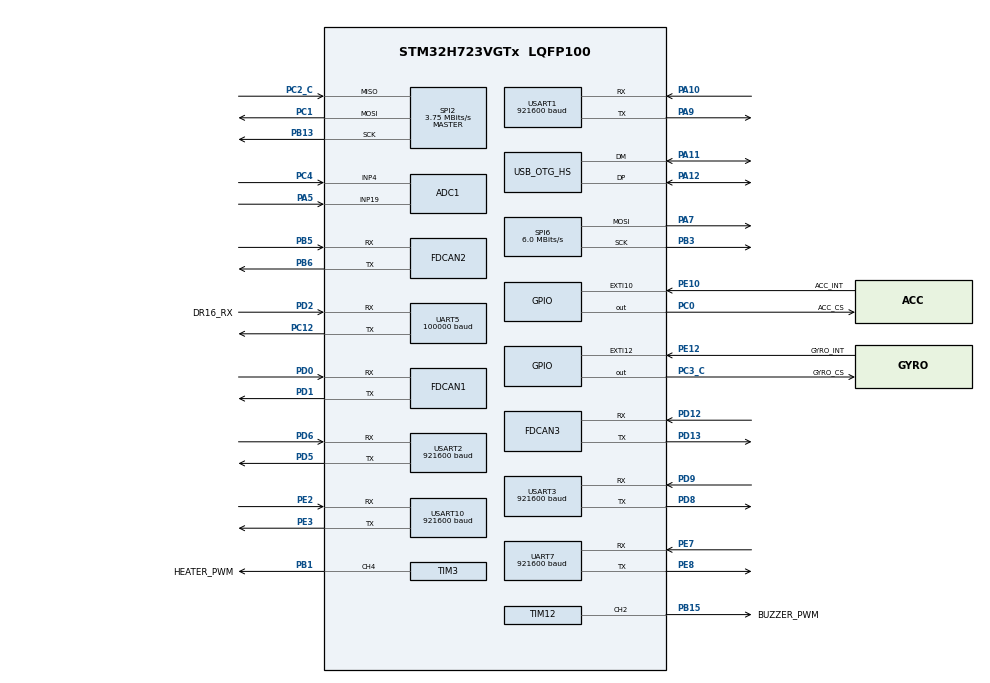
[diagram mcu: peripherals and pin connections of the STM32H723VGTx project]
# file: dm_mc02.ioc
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ADC1.Channel-0\#ChannelRegularConversion=ADC_CHANNEL_4
ADC1.Channel-1\#ChannelRegularConversion=ADC_CHANNEL_19
ADC1.ClockPrescaler=ADC_CLOCK_ASYNC_DIV1
ADC1.ContinuousConvMode=ENABLE
ADC1.ConversionDataManagement=ADC_CONVERSIONDATA_DMA_CIRCULAR
ADC1.NbrOfConversion=2
ADC1.NbrOfConversionFlag=1
ADC1.OffsetNumber-0\#ChannelRegularConversion=ADC_OFFSET_NONE
ADC1.OffsetNumber-1\#ChannelRegularConversion=ADC_OFFSET_NONE
ADC1.OffsetSignedSaturation-0\#ChannelRegularConversion=DISABLE
ADC1.OffsetSignedSaturation-1\#ChannelRegularConversion=DISABLE
ADC1.Rank-0\#ChannelRegularConversion=1
ADC1.Rank-1\#ChannelRegularConversion=2
ADC1.SamplingTime-0\#ChannelRegularConversion=ADC_SAMPLETIME_32CYCLES_5
ADC1.SamplingTime-1\#ChannelRegularConversion=ADC_SAMPLETIME_32CYCLES_5
ADC1.master=1
CORTEX_M7.CPU_DCache=Enabled
CORTEX_M7.CPU_ICache=Enabled
CORTEX_M7.default_mode_Activation=1
Dma.ADC1.0.Direction=DMA_PERIPH_TO_MEMORY
Dma.ADC1.0.EventEnable=DISABLE
Dma.ADC1.0.FIFOMode=DMA_FIFOMODE_DISABLE
Dma.ADC1.0.Instance=DMA1_Stream0
Dma.ADC1.0.MemDataAlignment=DMA_MDATAALIGN_HALFWORD
Dma.ADC1.0.MemInc=DMA_MINC_ENABLE
Dma.ADC1.0.Mode=DMA_CIRCULAR
Dma.ADC1.0.PeriphDataAlignment=DMA_PDATAALIGN_HALFWORD
Dma.ADC1.0.PeriphInc=DMA_PINC_DISABLE
Dma.ADC1.0.Polarity=HAL_DMAMUX_REQ_GEN_RISING
Dma.ADC1.0.Priority=DMA_PRIORITY_LOW
Dma.ADC1.0.RequestNumber=1
Dma.ADC1.0.SignalID=NONE
Dma.ADC1.0.SyncEnable=DISABLE
Dma.ADC1.0.SyncPolarity=HAL_DMAMUX_SYNC_NO_EVENT
Dma.ADC1.0.SyncRequestNumber=1
Dma.ADC1.0.SyncSignalID=NONE
Dma.Request0=ADC1
Dma.Request1=UART5_RX
Dma.Request10=USART10_RX
Dma.Request11=USART10_TX
Dma.Request12=USART1_RX
Dma.Request13=USART1_TX
Dma.Request2=SPI2_RX
Dma.Request3=SPI2_TX
Dma.Request4=UART7_RX
Dma.Request5=UART7_TX
Dma.Request6=USART2_RX
Dma.Request7=USART2_TX
Dma.Request8=USART3_RX
Dma.Request9=USART3_TX
Dma.SPI2_RX.2.Direction=DMA_PERIPH_TO_MEMORY
Dma.SPI2_RX.2.EventEnable=DISABLE
Dma.SPI2_RX.2.FIFOMode=DMA_FIFOMODE_DISABLE
Dma.SPI2_RX.2.Instance=DMA1_Stream2
Dma.SPI2_RX.2.MemDataAlignment=DMA_MDATAALIGN_BYTE
Dma.SPI2_RX.2.MemInc=DMA_MINC_ENABLE
Dma.SPI2_RX.2.Mode=DMA_NORMAL
Dma.SPI2_RX.2.PeriphDataAlignment=DMA_PDATAALIGN_BYTE
Dma.SPI2_RX.2.PeriphInc=DMA_PINC_DISABLE
Dma.SPI2_RX.2.Polarity=HAL_DMAMUX_REQ_GEN_RISING
Dma.SPI2_RX.2.Priority=DMA_PRIORITY_LOW
Dma.SPI2_RX.2.RequestNumber=1
Dma.SPI2_RX.2.SignalID=NONE
Dma.SPI2_RX.2.SyncEnable=DISABLE
Dma.SPI2_RX.2.SyncPolarity=HAL_DMAMUX_SYNC_NO_EVENT
Dma.SPI2_RX.2.SyncRequestNumber=1
Dma.SPI2_RX.2.SyncSignalID=NONE
Dma.SPI2_TX.3.Direction=DMA_MEMORY_TO_PERIPH
Dma.SPI2_TX.3.EventEnable=DISABLE
Dma.SPI2_TX.3.FIFOMode=DMA_FIFOMODE_DISABLE
Dma.SPI2_TX.3.Instance=DMA1_Stream3
Dma.SPI2_TX.3.MemDataAlignment=DMA_MDATAALIGN_BYTE
Dma.SPI2_TX.3.MemInc=DMA_MINC_ENABLE
Dma.SPI2_TX.3.Mode=DMA_NORMAL
Dma.SPI2_TX.3.PeriphDataAlignment=DMA_PDATAALIGN_BYTE
Dma.SPI2_TX.3.PeriphInc=DMA_PINC_DISABLE
Dma.SPI2_TX.3.Polarity=HAL_DMAMUX_REQ_GEN_RISING
Dma.SPI2_TX.3.Priority=DMA_PRIORITY_LOW
Dma.SPI2_TX.3.RequestNumber=1
Dma.SPI2_TX.3.SignalID=NONE
Dma.SPI2_TX.3.SyncEnable=DISABLE
Dma.SPI2_TX.3.SyncPolarity=HAL_DMAMUX_SYNC_NO_EVENT
Dma.SPI2_TX.3.SyncRequestNumber=1
Dma.SPI2_TX.3.SyncSignalID=NONE
Dma.UART5_RX.1.Direction=DMA_PERIPH_TO_MEMORY
Dma.UART5_RX.1.EventEnable=DISABLE
Dma.UART5_RX.1.FIFOMode=DMA_FIFOMODE_DISABLE
Dma.UART5_RX.1.Instance=DMA1_Stream1
Dma.UART5_RX.1.MemDataAlignment=DMA_MDATAALIGN_BYTE
Dma.UART5_RX.1.MemInc=DMA_MINC_ENABLE
Dma.UART5_RX.1.Mode=DMA_NORMAL
Dma.UART5_RX.1.PeriphDataAlignment=DMA_PDATAALIGN_BYTE
Dma.UART5_RX.1.PeriphInc=DMA_PINC_DISABLE
Dma.UART5_RX.1.Polarity=HAL_DMAMUX_REQ_GEN_RISING
Dma.UART5_RX.1.Priority=DMA_PRIORITY_LOW
Dma.UART5_RX.1.RequestNumber=1
Dma.UART5_RX.1.SignalID=NONE
Dma.UART5_RX.1.SyncEnable=DISABLE
Dma.UART5_RX.1.SyncPolarity=HAL_DMAMUX_SYNC_NO_EVENT
Dma.UART5_RX.1.SyncRequestNumber=1
Dma.UART5_RX.1.SyncSignalID=NONE
Dma.UART7_RX.4.Direction=DMA_PERIPH_TO_MEMORY
Dma.UART7_RX.4.EventEnable=DISABLE
Dma.UART7_RX.4.FIFOMode=DMA_FIFOMODE_DISABLE
Dma.UART7_RX.4.Instance=DMA1_Stream4
Dma.UART7_RX.4.MemDataAlignment=DMA_MDATAALIGN_BYTE
Dma.UART7_RX.4.MemInc=DMA_MINC_ENABLE
Dma.UART7_RX.4.Mode=DMA_NORMAL
Dma.UART7_RX.4.PeriphDataAlignment=DMA_PDATAALIGN_BYTE
Dma.UART7_RX.4.PeriphInc=DMA_PINC_DISABLE
Dma.UART7_RX.4.Polarity=HAL_DMAMUX_REQ_GEN_RISING
Dma.UART7_RX.4.Priority=DMA_PRIORITY_LOW
Dma.UART7_RX.4.RequestNumber=1
Dma.UART7_RX.4.SignalID=NONE
Dma.UART7_RX.4.SyncEnable=DISABLE
Dma.UART7_RX.4.SyncPolarity=HAL_DMAMUX_SYNC_NO_EVENT
Dma.UART7_RX.4.SyncRequestNumber=1
Dma.UART7_RX.4.SyncSignalID=NONE
Dma.UART7_TX.5.Direction=DMA_MEMORY_TO_PERIPH
Dma.UART7_TX.5.EventEnable=DISABLE
Dma.UART7_TX.5.FIFOMode=DMA_FIFOMODE_DISABLE
Dma.UART7_TX.5.Instance=DMA1_Stream5
Dma.UART7_TX.5.MemDataAlignment=DMA_MDATAALIGN_BYTE
Dma.UART7_TX.5.MemInc=DMA_MINC_ENABLE
Dma.UART7_TX.5.Mode=DMA_NORMAL
Dma.UART7_TX.5.PeriphDataAlignment=DMA_PDATAALIGN_BYTE
Dma.UART7_TX.5.PeriphInc=DMA_PINC_DISABLE
Dma.UART7_TX.5.Polarity=HAL_DMAMUX_REQ_GEN_RISING
Dma.UART7_TX.5.Priority=DMA_PRIORITY_LOW
Dma.UART7_TX.5.RequestNumber=1
Dma.UART7_TX.5.SignalID=NONE
Dma.UART7_TX.5.SyncEnable=DISABLE
Dma.UART7_TX.5.SyncPolarity=HAL_DMAMUX_SYNC_NO_EVENT
Dma.UART7_TX.5.SyncRequestNumber=1
Dma.UART7_TX.5.SyncSignalID=NONE
Dma.USART10_RX.10.Direction=DMA_PERIPH_TO_MEMORY
Dma.USART10_RX.10.EventEnable=DISABLE
Dma.USART10_RX.10.FIFOMode=DMA_FIFOMODE_DISABLE
Dma.USART10_RX.10.Instance=DMA2_Stream4
Dma.USART10_RX.10.MemDataAlignment=DMA_MDATAALIGN_BYTE
Dma.USART10_RX.10.MemInc=DMA_MINC_ENABLE
Dma.USART10_RX.10.Mode=DMA_NORMAL
Dma.USART10_RX.10.PeriphDataAlignment=DMA_PDATAALIGN_BYTE
Dma.USART10_RX.10.PeriphInc=DMA_PINC_DISABLE
Dma.USART10_RX.10.Polarity=HAL_DMAMUX_REQ_GEN_RISING
Dma.USART10_RX.10.Priority=DMA_PRIORITY_LOW
Dma.USART10_RX.10.RequestNumber=1
Dma.USART10_RX.10.SignalID=NONE
Dma.USART10_RX.10.SyncEnable=DISABLE
Dma.USART10_RX.10.SyncPolarity=HAL_DMAMUX_SYNC_NO_EVENT
Dma.USART10_RX.10.SyncRequestNumber=1
Dma.USART10_RX.10.SyncSignalID=NONE
Dma.USART10_TX.11.Direction=DMA_MEMORY_TO_PERIPH
Dma.USART10_TX.11.EventEnable=DISABLE
Dma.USART10_TX.11.FIFOMode=DMA_FIFOMODE_DISABLE
Dma.USART10_TX.11.Instance=DMA2_Stream5
Dma.USART10_TX.11.MemDataAlignment=DMA_MDATAALIGN_BYTE
Dma.USART10_TX.11.MemInc=DMA_MINC_ENABLE
Dma.USART10_TX.11.Mode=DMA_NORMAL
Dma.USART10_TX.11.PeriphDataAlignment=DMA_PDATAALIGN_BYTE
Dma.USART10_TX.11.PeriphInc=DMA_PINC_DISABLE
Dma.USART10_TX.11.Polarity=HAL_DMAMUX_REQ_GEN_RISING
Dma.USART10_TX.11.Priority=DMA_PRIORITY_LOW
Dma.USART10_TX.11.RequestNumber=1
Dma.USART10_TX.11.SignalID=NONE
Dma.USART10_TX.11.SyncEnable=DISABLE
Dma.USART10_TX.11.SyncPolarity=HAL_DMAMUX_SYNC_NO_EVENT
Dma.USART10_TX.11.SyncRequestNumber=1
Dma.USART10_TX.11.SyncSignalID=NONE
Dma.USART1_RX.12.Direction=DMA_PERIPH_TO_MEMORY
Dma.USART1_RX.12.EventEnable=DISABLE
Dma.USART1_RX.12.FIFOMode=DMA_FIFOMODE_DISABLE
Dma.USART1_RX.12.Instance=DMA1_Stream6
Dma.USART1_RX.12.MemDataAlignment=DMA_MDATAALIGN_BYTE
Dma.USART1_RX.12.MemInc=DMA_MINC_ENABLE
Dma.USART1_RX.12.Mode=DMA_NORMAL
Dma.USART1_RX.12.PeriphDataAlignment=DMA_PDATAALIGN_BYTE
Dma.USART1_RX.12.PeriphInc=DMA_PINC_DISABLE
Dma.USART1_RX.12.Polarity=HAL_DMAMUX_REQ_GEN_RISING
Dma.USART1_RX.12.Priority=DMA_PRIORITY_LOW
Dma.USART1_RX.12.RequestNumber=1
Dma.USART1_RX.12.SignalID=NONE
Dma.USART1_RX.12.SyncEnable=DISABLE
Dma.USART1_RX.12.SyncPolarity=HAL_DMAMUX_SYNC_NO_EVENT
Dma.USART1_RX.12.SyncRequestNumber=1
Dma.USART1_RX.12.SyncSignalID=NONE
Dma.USART1_TX.13.Direction=DMA_MEMORY_TO_PERIPH
Dma.USART1_TX.13.EventEnable=DISABLE
Dma.USART1_TX.13.FIFOMode=DMA_FIFOMODE_DISABLE
Dma.USART1_TX.13.Instance=DMA1_Stream7
Dma.USART1_TX.13.MemDataAlignment=DMA_MDATAALIGN_BYTE
Dma.USART1_TX.13.MemInc=DMA_MINC_ENABLE
Dma.USART1_TX.13.Mode=DMA_NORMAL
Dma.USART1_TX.13.PeriphDataAlignment=DMA_PDATAALIGN_BYTE
Dma.USART1_TX.13.PeriphInc=DMA_PINC_DISABLE
Dma.USART1_TX.13.Polarity=HAL_DMAMUX_REQ_GEN_RISING
Dma.USART1_TX.13.Priority=DMA_PRIORITY_LOW
Dma.USART1_TX.13.RequestNumber=1
Dma.USART1_TX.13.SignalID=NONE
Dma.USART1_TX.13.SyncEnable=DISABLE
Dma.USART1_TX.13.SyncPolarity=HAL_DMAMUX_SYNC_NO_EVENT
Dma.USART1_TX.13.SyncRequestNumber=1
Dma.USART1_TX.13.SyncSignalID=NONE
Dma.USART2_RX.6.Direction=DMA_PERIPH_TO_MEMORY
Dma.USART2_RX.6.EventEnable=DISABLE
Dma.USART2_RX.6.FIFOMode=DMA_FIFOMODE_DISABLE
Dma.USART2_RX.6.Instance=DMA2_Stream0
Dma.USART2_RX.6.MemDataAlignment=DMA_MDATAALIGN_BYTE
Dma.USART2_RX.6.MemInc=DMA_MINC_ENABLE
Dma.USART2_RX.6.Mode=DMA_NORMAL
Dma.USART2_RX.6.PeriphDataAlignment=DMA_PDATAALIGN_BYTE
Dma.USART2_RX.6.PeriphInc=DMA_PINC_DISABLE
Dma.USART2_RX.6.Polarity=HAL_DMAMUX_REQ_GEN_RISING
Dma.USART2_RX.6.Priority=DMA_PRIORITY_LOW
Dma.USART2_RX.6.RequestNumber=1
Dma.USART2_RX.6.SignalID=NONE
Dma.USART2_RX.6.SyncEnable=DISABLE
Dma.USART2_RX.6.SyncPolarity=HAL_DMAMUX_SYNC_NO_EVENT
Dma.USART2_RX.6.SyncRequestNumber=1
Dma.USART2_RX.6.SyncSignalID=NONE
Dma.USART2_TX.7.Direction=DMA_MEMORY_TO_PERIPH
Dma.USART2_TX.7.EventEnable=DISABLE
Dma.USART2_TX.7.FIFOMode=DMA_FIFOMODE_DISABLE
Dma.USART2_TX.7.Instance=DMA2_Stream1
Dma.USART2_TX.7.MemDataAlignment=DMA_MDATAALIGN_BYTE
Dma.USART2_TX.7.MemInc=DMA_MINC_ENABLE
Dma.USART2_TX.7.Mode=DMA_NORMAL
Dma.USART2_TX.7.PeriphDataAlignment=DMA_PDATAALIGN_BYTE
Dma.USART2_TX.7.PeriphInc=DMA_PINC_DISABLE
Dma.USART2_TX.7.Polarity=HAL_DMAMUX_REQ_GEN_RISING
Dma.USART2_TX.7.Priority=DMA_PRIORITY_LOW
Dma.USART2_TX.7.RequestNumber=1
Dma.USART2_TX.7.SignalID=NONE
Dma.USART2_TX.7.SyncEnable=DISABLE
Dma.USART2_TX.7.SyncPolarity=HAL_DMAMUX_SYNC_NO_EVENT
Dma.USART2_TX.7.SyncRequestNumber=1
Dma.USART2_TX.7.SyncSignalID=NONE
Dma.USART3_RX.8.Direction=DMA_PERIPH_TO_MEMORY
Dma.USART3_RX.8.EventEnable=DISABLE
Dma.USART3_RX.8.FIFOMode=DMA_FIFOMODE_DISABLE
Dma.USART3_RX.8.Instance=DMA2_Stream2
Dma.USART3_RX.8.MemDataAlignment=DMA_MDATAALIGN_BYTE
Dma.USART3_RX.8.MemInc=DMA_MINC_ENABLE
Dma.USART3_RX.8.Mode=DMA_NORMAL
Dma.USART3_RX.8.PeriphDataAlignment=DMA_PDATAALIGN_BYTE
Dma.USART3_RX.8.PeriphInc=DMA_PINC_DISABLE
Dma.USART3_RX.8.Polarity=HAL_DMAMUX_REQ_GEN_RISING
Dma.USART3_RX.8.Priority=DMA_PRIORITY_LOW
Dma.USART3_RX.8.RequestNumber=1
Dma.USART3_RX.8.SignalID=NONE
Dma.USART3_RX.8.SyncEnable=DISABLE
Dma.USART3_RX.8.SyncPolarity=HAL_DMAMUX_SYNC_NO_EVENT
Dma.USART3_RX.8.SyncRequestNumber=1
Dma.USART3_RX.8.SyncSignalID=NONE
Dma.USART3_TX.9.Direction=DMA_MEMORY_TO_PERIPH
Dma.USART3_TX.9.EventEnable=DISABLE
Dma.USART3_TX.9.FIFOMode=DMA_FIFOMODE_DISABLE
Dma.USART3_TX.9.Instance=DMA2_Stream3
Dma.USART3_TX.9.MemDataAlignment=DMA_MDATAALIGN_BYTE
Dma.USART3_TX.9.MemInc=DMA_MINC_ENABLE
Dma.USART3_TX.9.Mode=DMA_NORMAL
Dma.USART3_TX.9.PeriphDataAlignment=DMA_PDATAALIGN_BYTE
Dma.USART3_TX.9.PeriphInc=DMA_PINC_DISABLE
Dma.USART3_TX.9.Polarity=HAL_DMAMUX_REQ_GEN_RISING
Dma.USART3_TX.9.Priority=DMA_PRIORITY_LOW
Dma.USART3_TX.9.RequestNumber=1
Dma.USART3_TX.9.SignalID=NONE
Dma.USART3_TX.9.SyncEnable=DISABLE
Dma.USART3_TX.9.SyncPolarity=HAL_DMAMUX_SYNC_NO_EVENT
Dma.USART3_TX.9.SyncRequestNumber=1
Dma.USART3_TX.9.SyncSignalID=NONE
FDCAN1.AutoRetransmission=ENABLE
FDCAN1.CalculateBaudRateNominal=1000000
FDCAN1.CalculateTimeBitNominal=1000
FDCAN1.CalculateTimeQuantumNominal=25.0
FDCAN1.NominalPrescaler=3
FDCAN1.NominalTimeSeg1=29
FDCAN1.NominalTimeSeg2=10
FDCAN1.RxFifo0ElmtsNbr=32
FDCAN1.StdFiltersNbr=1
FDCAN1.TxFifoQueueElmtsNbr=32
FDCAN2.AutoRetransmission=ENABLE
FDCAN2.CalculateBaudRateNominal=1000000
FDCAN2.CalculateTimeBitNominal=1000
FDCAN2.CalculateTimeQuantumNominal=25.0
FDCAN2.MessageRAMOffset=0x406
FDCAN2.NominalPrescaler=3
FDCAN2.NominalTimeSeg1=29
FDCAN2.NominalTimeSeg2=10
FDCAN2.ProtocolException=DISABLE
FDCAN2.RxFifo1ElmtsNbr=32
FDCAN2.StdFiltersNbr=1
FDCAN2.TransmitPause=DISABLE
FDCAN2.TxEventsNbr=8
FDCAN2.TxFifoQueueElmtsNbr=32
FDCAN3.AutoRetransmission=ENABLE
FDCAN3.CalculateBaudRateNominal=1000000
FDCAN3.CalculateTimeBitNominal=1000
FDCAN3.CalculateTimeQuantumNominal=25.0
FDCAN3.MessageRAMOffset=0x812
FDCAN3.NominalPrescaler=3
FDCAN3.NominalTimeSeg1=29
FDCAN3.NominalTimeSeg2=10
FDCAN3.RxFifo1ElmtsNbr=32
FDCAN3.StdFiltersNbr=1
FDCAN3.TxEventsNbr=4
FDCAN3.TxFifoQueueElmtsNbr=32
FREERTOS.Tasks01=defaultTask,24,128,StartDefaultTask,Default,NULL,Dynamic,NULL,NULL
Mcu.Family=STM32H7
Mcu.Name=STM32H723VGTx
Mcu.Package=LQFP100
NVIC.DMA1_Stream0_IRQn=true\:5\:0\:false\:false\:true\:true\:false\:true\:true
NVIC.DMA1_Stream1_IRQn=true\:5\:0\:false\:false\:true\:true\:false\:true\:true
NVIC.DMA1_Stream2_IRQn=true\:5\:0\:false\:false\:true\:true\:false\:true\:true
NVIC.DMA1_Stream3_IRQn=true\:5\:0\:false\:false\:true\:true\:false\:true\:true
NVIC.DMA1_Stream4_IRQn=true\:5\:0\:false\:false\:true\:true\:false\:true\:true
NVIC.DMA1_Stream5_IRQn=true\:5\:0\:false\:false\:true\:true\:false\:true\:true
NVIC.DMA1_Stream6_IRQn=true\:5\:0\:false\:false\:true\:true\:false\:true\:true
NVIC.DMA1_Stream7_IRQn=true\:5\:0\:false\:false\:true\:true\:false\:true\:true
NVIC.DMA2_Stream0_IRQn=true\:5\:0\:false\:false\:true\:true\:false\:true\:true
NVIC.DMA2_Stream1_IRQn=true\:5\:0\:false\:false\:true\:true\:false\:true\:true
NVIC.DMA2_Stream2_IRQn=true\:5\:0\:false\:false\:true\:true\:false\:true\:true
NVIC.DMA2_Stream3_IRQn=true\:5\:0\:false\:false\:true\:true\:false\:true\:true
NVIC.DMA2_Stream4_IRQn=true\:5\:0\:false\:false\:true\:true\:false\:true\:true
NVIC.DMA2_Stream5_IRQn=true\:5\:0\:false\:false\:true\:true\:false\:true\:true
NVIC.EXTI15_10_IRQn=true\:5\:0\:true\:false\:true\:true\:true\:true\:true
NVIC.FDCAN1_IT0_IRQn=true\:5\:0\:false\:false\:true\:true\:true\:true\:true
NVIC.FDCAN1_IT1_IRQn=true\:5\:0\:false\:false\:true\:true\:true\:true\:true
NVIC.FDCAN2_IT0_IRQn=true\:5\:0\:false\:false\:true\:true\:true\:true\:true
NVIC.FDCAN2_IT1_IRQn=true\:5\:0\:false\:false\:true\:true\:true\:true\:true
NVIC.FDCAN3_IT0_IRQn=true\:5\:0\:false\:false\:true\:true\:true\:true\:true
NVIC.FDCAN3_IT1_IRQn=true\:5\:0\:false\:false\:true\:true\:true\:true\:true
NVIC.OTG_HS_IRQn=true\:5\:0\:false\:false\:true\:true\:false\:true\:true
NVIC.PriorityGroup=NVIC_PRIORITYGROUP_4
NVIC.SPI2_IRQn=true\:5\:0\:false\:false\:true\:true\:false\:true\:true
NVIC.TIM4_IRQn=true\:15\:0\:false\:false\:true\:false\:false\:true\:true
NVIC.TimeBase=TIM4_IRQn
NVIC.TimeBaseIP=TIM4
NVIC.UART5_IRQn=true\:5\:0\:false\:false\:true\:true\:true\:true\:true
NVIC.UART7_IRQn=true\:5\:0\:false\:false\:true\:true\:true\:true\:true
NVIC.USART10_IRQn=true\:5\:0\:false\:false\:true\:true\:true\:true\:true
NVIC.USART2_IRQn=true\:5\:0\:false\:false\:true\:true\:true\:true\:true
NVIC.USART3_IRQn=true\:5\:0\:false\:false\:true\:true\:true\:true\:true
PA10.GPIO_PuPd=GPIO_PULLUP
PA10.Mode=Asynchronous
PA10.Signal=USART1_RX
PA11.Mode=Device_Only_FS
PA11.Signal=USB_OTG_HS_DM
PA12.Mode=Device_Only_FS
PA12.Signal=USB_OTG_HS_DP
PA5.Signal=ADCx_INP19
PA7.Mode=TX_Only_Simplex_Unidirect_Master
PA7.Signal=SPI6_MOSI
PA9.Mode=Asynchronous
PA9.Signal=USART1_TX
PB1.GPIO_Label=HEATER_PWM
PB1.Signal=S_TIM3_CH4
PB13.GPIO_Speed=GPIO_SPEED_FREQ_VERY_HIGH
PB13.Mode=Full_Duplex_Master
PB13.Signal=SPI2_SCK
PB15.GPIO_Label=BUZZER_PWM
PB15.Signal=S_TIM12_CH2
PB3(JTDO/TRACESWO).Mode=TX_Only_Simplex_Unidirect_Master
PB3(JTDO/TRACESWO).Signal=SPI6_SCK
PB5.Mode=FDCAN_Activate
PB5.Signal=FDCAN2_RX
PB6.Mode=FDCAN_Activate
PB6.Signal=FDCAN2_TX
PC0.GPIO_Label=ACC_CS
PC0.GPIO_Speed=GPIO_SPEED_FREQ_VERY_HIGH
PC0.PinState=GPIO_PIN_SET
PC0.Signal=GPIO_Output
PC1.GPIO_Speed=GPIO_SPEED_FREQ_VERY_HIGH
PC1.Mode=Full_Duplex_Master
PC1.Signal=SPI2_MOSI
PC12.Mode=Asynchronous
PC12.Signal=UART5_TX
PC2_C.GPIO_Speed=GPIO_SPEED_FREQ_VERY_HIGH
PC2_C.Mode=Full_Duplex_Master
PC2_C.Signal=SPI2_MISO
PC3_C.GPIO_Label=GYRO_CS
PC3_C.GPIO_Speed=GPIO_SPEED_FREQ_VERY_HIGH
PC3_C.PinState=GPIO_PIN_SET
PC3_C.Signal=GPIO_Output
PC4.Signal=ADCx_INP4
PD0.Mode=FDCAN_Activate
PD0.Signal=FDCAN1_RX
PD1.Mode=FDCAN_Activate
PD1.Signal=FDCAN1_TX
PD12.Mode=FDCAN_Activate
PD12.Signal=FDCAN3_RX
PD13.Mode=FDCAN_Activate
PD13.Signal=FDCAN3_TX
PD2.GPIO_Label=DR16_RX
PD2.GPIO_PuPd=GPIO_PULLUP
PD2.Mode=Asynchronous
PD2.Signal=UART5_RX
PD5.Mode=Asynchronous
PD5.Signal=USART2_TX
PD6.GPIO_PuPd=GPIO_PULLUP
PD6.Mode=Asynchronous
PD6.Signal=USART2_RX
PD8.Mode=Asynchronous
PD8.Signal=USART3_TX
PD9.GPIO_PuPd=GPIO_PULLUP
PD9.Mode=Asynchronous
PD9.Signal=USART3_RX
PE10.GPIO_Label=ACC_INT
PE10.GPIO_PuPd=GPIO_NOPULL
PE10.Signal=GPXTI10
PE12.GPIO_Label=GYRO_INT
PE12.GPIO_PuPd=GPIO_NOPULL
PE12.Signal=GPXTI12
PE2.GPIO_PuPd=GPIO_PULLUP
PE2.Mode=Asynchronous
PE2.Signal=USART10_RX
PE3.Mode=Asynchronous
PE3.Signal=USART10_TX
PE7.GPIO_PuPd=GPIO_PULLUP
PE7.Mode=Asynchronous
PE7.Signal=UART7_RX
PE8.Mode=Asynchronous
PE8.Signal=UART7_TX
PH0-OSC_IN.Mode=HSE-External-Oscillator
PH0-OSC_IN.Signal=RCC_OSC_IN
PH1-OSC_OUT.Mode=HSE-External-Oscillator
PH1-OSC_OUT.Signal=RCC_OSC_OUT
ProjectManager.HeapSize=0x200
ProjectManager.StackSize=0x400
ProjectManager.TargetToolchain=CMake
RCC.ADCCLockSelection=RCC_ADCCLKSOURCE_PLL3
RCC.ADCFreq_Value=48000000
RCC.APB1Freq_Value=120000000
RCC.APB2Freq_Value=120000000
RCC.APB3Freq_Value=120000000
RCC.APB4Freq_Value=120000000
RCC.CKPERSourceSelection=RCC_CLKPSOURCE_HSE
RCC.CortexFreq_Value=480000000
RCC.D1PPRE=RCC_APB3_DIV2
RCC.D2PPRE1=RCC_APB1_DIV2
RCC.D2PPRE2=RCC_APB2_DIV2
RCC.D3PPRE=RCC_APB4_DIV2
RCC.DIVM1=2
RCC.DIVM2=2
RCC.DIVM3=2
RCC.DIVN1=40
RCC.DIVN2=32
RCC.DIVN3=16
RCC.DIVP1=1
RCC.DIVQ1=4
RCC.DIVR3=4
RCC.HCLKFreq_Value=240000000
RCC.HPRE=RCC_HCLK_DIV2
RCC.HSE_VALUE=24000000
RCC.PLL1_VCI_Range-AdvancedSettings=RCC_PLL1VCIRANGE_3
RCC.PLL1_VCO_SEL-AdvancedSettings=RCC_PLL1VCOWIDE
RCC.PLL2FRACN=0
RCC.PLL2_VCI_Range-AdvancedSettings=RCC_PLL2VCIRANGE_3
RCC.PLL2_VCO_SEL-AdvancedSettings=RCC_PLL2VCOWIDE
RCC.PLL3FRACN=0
RCC.PLL3_VCO_SEL-AdvancedSettings=RCC_PLL3VCOWIDE
RCC.PLLFRACN=0
RCC.PLLSourceVirtual=RCC_PLLSOURCE_HSE
RCC.SPI6CLockSelection=RCC_SPI6CLKSOURCE_HSE
RCC.SYSCLKFreq_VALUE=480000000
RCC.SYSCLKSource=RCC_SYSCLKSOURCE_PLLCLK
RCC.USBCLockSelection=RCC_USBCLKSOURCE_HSI48
RCC.USBFreq_Value=48000000
SH.ADCx_INP19.0=ADC1_INP19,IN19-Single-Ended
SH.ADCx_INP4.0=ADC1_INP4,IN4-Single-Ended
SH.S_TIM12_CH2.0=TIM12_CH2,PWM Generation2 CH2
SH.S_TIM3_CH4.0=TIM3_CH4,PWM Generation4 CH4
SPI2.BaudRatePrescaler=SPI_BAUDRATEPRESCALER_32
SPI2.CLKPhase=SPI_PHASE_2EDGE
SPI2.CLKPolarity=SPI_POLARITY_HIGH
SPI2.CalculateBaudRate=3.75 MBits/s
SPI2.DataSize=SPI_DATASIZE_8BIT
SPI2.Direction=SPI_DIRECTION_2LINES
SPI2.Mode=SPI_MODE_MASTER
SPI2.VirtualType=VM_MASTER
SPI6.BaudRatePrescaler=SPI_BAUDRATEPRESCALER_4
SPI6.CalculateBaudRate=6.0 MBits/s
SPI6.DataSize=SPI_DATASIZE_8BIT
SPI6.Direction=SPI_DIRECTION_2LINES_TXONLY
SPI6.Mode=SPI_MODE_MASTER
SPI6.VirtualType=VM_MASTER
TIM12.Channel-PWM\ Generation2\ CH2=TIM_CHANNEL_2
TIM12.OC2Preload_PWM=DISABLE
TIM12.Period=250-1
TIM12.Prescaler=240-1
TIM3.Channel-PWM\ Generation4\ CH4=TIM_CHANNEL_4
TIM3.Period=10000-1
TIM3.Prescaler=240-1
UART5.BaudRate=100000
UART5.Mode=MODE_RX
UART5.Parity=PARITY_EVEN
UART5.StopBits=UART_STOPBITS_2
UART5.WordLength=WORDLENGTH_9B
UART7.BaudRate=921600
USART1.BaudRate=921600
USART1.VirtualMode-Asynchronous=VM_ASYNC
USART10.BaudRate=921600
USART10.VirtualMode=VM_ASYNC
USART2.BaudRate=921600
USART2.VirtualMode-Asynchronous=VM_ASYNC
USART3.BaudRate=921600
USART3.VirtualMode-Asynchronous=VM_ASYNC
USB_DEVICE.CLASS_NAME_HS=CDC
USB_DEVICE.VirtualMode=Cdc
USB_DEVICE.VirtualModeHS=Cdc_HS
USB_OTG_HS.VirtualMode-Device_Only_FS=Device_Only_FS
VP_FREERTOS_VS_CMSIS_V2.Mode=CMSIS_V2
VP_MEMORYMAP_VS_MEMORYMAP.Mode=CurAppReg
VP_SYS_VS_tim4.Mode=TIM4
VP_USB_DEVICE_VS_USB_DEVICE_CDC_HS.Mode=CDC_HS
board=custom

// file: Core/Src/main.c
/* USER CODE BEGIN Header */
/**
  ******************************************************************************
  * @file           : main.c
  * @brief          : Main program body
  ******************************************************************************
  * @attention
  *
  * Copyright (c) 2026 STMicroelectronics.
  * All rights reserved.
  *
  * This software is licensed under terms that can be found in the LICENSE file
  * in the root directory of this software component.
  * If no LICENSE file comes with this software, it is provided AS-IS.
  *
  ******************************************************************************
  */
/* USER CODE END Header */
#include "main.h"
#include "FreeRTOS.h"
#include "cmsis_os2.h"
#include "usb_device.h"

ADC_HandleTypeDef hadc1;
DMA_HandleTypeDef hdma_adc1;

FDCAN_HandleTypeDef hfdcan1;
FDCAN_HandleTypeDef hfdcan2;
FDCAN_HandleTypeDef hfdcan3;

SPI_HandleTypeDef hspi2;
SPI_HandleTypeDef hspi6;
DMA_HandleTypeDef hdma_spi2_rx;
DMA_HandleTypeDef hdma_spi2_tx;

TIM_HandleTypeDef htim3;
TIM_HandleTypeDef htim12;

UART_HandleTypeDef huart5;
UART_HandleTypeDef huart7;
UART_HandleTypeDef huart1;
UART_HandleTypeDef huart2;
UART_HandleTypeDef huart3;
UART_HandleTypeDef huart10;
DMA_HandleTypeDef hdma_uart5_rx;
DMA_HandleTypeDef hdma_uart7_rx;
DMA_HandleTypeDef hdma_uart7_tx;
DMA_HandleTypeDef hdma_usart1_rx;
DMA_HandleTypeDef hdma_usart1_tx;
DMA_HandleTypeDef hdma_usart2_rx;
DMA_HandleTypeDef hdma_usart2_tx;
DMA_HandleTypeDef hdma_usart3_rx;
DMA_HandleTypeDef hdma_usart3_tx;
DMA_HandleTypeDef hdma_usart10_rx;
DMA_HandleTypeDef hdma_usart10_tx;

/* Definitions for defaultTask */
osThreadId_t defaultTaskHandle;
const osThreadAttr_t defaultTask_attributes = {
  .name = "defaultTask",
  .stack_size = 128 * 4,
  .priority = (osPriority_t) osPriorityNormal,
};

void SystemClock_Config(void);
static void MPU_Config(void);
static void MX_GPIO_Init(void);
static void MX_DMA_Init(void);
static void MX_ADC1_Init(void);
static void MX_UART5_Init(void);
static void MX_FDCAN1_Init(void);
static void MX_FDCAN2_Init(void);
static void MX_FDCAN3_Init(void);
static void MX_SPI2_Init(void);
static void MX_SPI6_Init(void);
static void MX_UART7_Init(void);
static void MX_USART2_UART_Init(void);
static void MX_USART3_UART_Init(void);
static void MX_USART10_UART_Init(void);
static void MX_USART1_UART_Init(void);
static void MX_TIM3_Init(void);
static void MX_TIM12_Init(void);
void StartDefaultTask(void *argument);

int main(void)
{

  /* MPU Configuration--------------------------------------------------------*/
  MPU_Config();

  /* Enable the CPU Cache */

  /* Enable I-Cache---------------------------------------------------------*/
  SCB_EnableICache();

  /* Enable D-Cache---------------------------------------------------------*/
  SCB_EnableDCache();

  /* MCU Configuration--------------------------------------------------------*/

  /* Reset of all peripherals, Initializes the Flash interface and the Systick. */
  HAL_Init();

  /* Configure the system clock */
  SystemClock_Config();

  /* Initialize all configured peripherals */
  MX_GPIO_Init();
  MX_DMA_Init();
  MX_ADC1_Init();
  MX_UART5_Init();
  MX_FDCAN1_Init();
  MX_FDCAN2_Init();
  MX_FDCAN3_Init();
  MX_SPI2_Init();
  MX_SPI6_Init();
  MX_UART7_Init();
  MX_USART2_UART_Init();
  MX_USART3_UART_Init();
  MX_USART10_UART_Init();
  MX_USART1_UART_Init();
  MX_TIM3_Init();
  MX_TIM12_Init();
  /* USER CODE BEGIN 2 */
  __HAL_TIM_SET_COMPARE(&htim3, TIM_CHANNEL_4, 0);
  __HAL_TIM_SET_COMPARE(&htim12, TIM_CHANNEL_2, 0);
  if (HAL_TIM_PWM_Start(&htim3, TIM_CHANNEL_4) != HAL_OK ||
      HAL_TIM_PWM_Start(&htim12, TIM_CHANNEL_2) != HAL_OK)
  {
    Error_Handler();
  }
  if (HAL_FDCAN_ConfigGlobalFilter(&hfdcan1, FDCAN_ACCEPT_IN_RX_FIFO0,
                                   FDCAN_ACCEPT_IN_RX_FIFO0, FDCAN_FILTER_REMOTE,
                                   FDCAN_FILTER_REMOTE) != HAL_OK ||
      HAL_FDCAN_ConfigGlobalFilter(&hfdcan2, FDCAN_ACCEPT_IN_RX_FIFO1,
                                   FDCAN_ACCEPT_IN_RX_FIFO1, FDCAN_FILTER_REMOTE,
                                   FDCAN_FILTER_REMOTE) != HAL_OK ||
      HAL_FDCAN_ConfigGlobalFilter(&hfdcan3, FDCAN_ACCEPT_IN_RX_FIFO1,
                                   FDCAN_ACCEPT_IN_RX_FIFO1, FDCAN_FILTER_REMOTE,
                                   FDCAN_FILTER_REMOTE) != HAL_OK)
  {
    Error_Handler();
  }
  /* USER CODE END 2 */

  /* Init scheduler */
  osKernelInitialize();

  /* Create the thread(s) */
  /* creation of defaultTask */
  defaultTaskHandle = osThreadNew(StartDefaultTask, NULL, &defaultTask_attributes);

  /* Start scheduler */
  osKernelStart();

  /* We should never get here as control is now taken by the scheduler */

  /* Infinite loop */
  while (1)
  {

  }
}

void SystemClock_Config(void)
{
  RCC_OscInitTypeDef RCC_OscInitStruct = {0};
  RCC_ClkInitTypeDef RCC_ClkInitStruct = {0};

  /** Supply configuration update enable
  */
  HAL_PWREx_ConfigSupply(PWR_LDO_SUPPLY);

  /** Configure the main internal regulator output voltage
  */
  __HAL_PWR_VOLTAGESCALING_CONFIG(PWR_REGULATOR_VOLTAGE_SCALE0);

  while(!__HAL_PWR_GET_FLAG(PWR_FLAG_VOSRDY)) {}

  /** Initializes the RCC Oscillators according to the specified parameters
  * in the RCC_OscInitTypeDef structure.
  */
  RCC_OscInitStruct.OscillatorType = RCC_OSCILLATORTYPE_HSI48|RCC_OSCILLATORTYPE_HSE;
  RCC_OscInitStruct.HSEState = RCC_HSE_ON;
  RCC_OscInitStruct.HSI48State = RCC_HSI48_ON;
  RCC_OscInitStruct.PLL.PLLState = RCC_PLL_ON;
  RCC_OscInitStruct.PLL.PLLSource = RCC_PLLSOURCE_HSE;
  RCC_OscInitStruct.PLL.PLLM = 2;
  RCC_OscInitStruct.PLL.PLLN = 40;
  RCC_OscInitStruct.PLL.PLLP = 1;
  RCC_OscInitStruct.PLL.PLLQ = 4;
  RCC_OscInitStruct.PLL.PLLR = 2;
  RCC_OscInitStruct.PLL.PLLRGE = RCC_PLL1VCIRANGE_3;
  RCC_OscInitStruct.PLL.PLLVCOSEL = RCC_PLL1VCOWIDE;
  RCC_OscInitStruct.PLL.PLLFRACN = 0;
  if (HAL_RCC_OscConfig(&RCC_OscInitStruct) != HAL_OK)
  {
    Error_Handler();
  }

  /** Initializes the CPU, AHB and APB buses clocks
  */
  RCC_ClkInitStruct.ClockType = RCC_CLOCKTYPE_HCLK|RCC_CLOCKTYPE_SYSCLK
                              |RCC_CLOCKTYPE_PCLK1|RCC_CLOCKTYPE_PCLK2
                              |RCC_CLOCKTYPE_D3PCLK1|RCC_CLOCKTYPE_D1PCLK1;
  RCC_ClkInitStruct.SYSCLKSource = RCC_SYSCLKSOURCE_PLLCLK;
  RCC_ClkInitStruct.SYSCLKDivider = RCC_SYSCLK_DIV1;
  RCC_ClkInitStruct.AHBCLKDivider = RCC_HCLK_DIV2;
  RCC_ClkInitStruct.APB3CLKDivider = RCC_APB3_DIV2;
  RCC_ClkInitStruct.APB1CLKDivider = RCC_APB1_DIV2;
  RCC_ClkInitStruct.APB2CLKDivider = RCC_APB2_DIV2;
  RCC_ClkInitStruct.APB4CLKDivider = RCC_APB4_DIV2;

  if (HAL_RCC_ClockConfig(&RCC_ClkInitStruct, FLASH_LATENCY_3) != HAL_OK)
  {
    Error_Handler();
  }
}

static void MX_ADC1_Init(void)
{

  ADC_MultiModeTypeDef multimode = {0};
  ADC_ChannelConfTypeDef sConfig = {0};

  /** Common config
  */
  hadc1.Instance = ADC1;
  hadc1.Init.ClockPrescaler = ADC_CLOCK_ASYNC_DIV1;
  hadc1.Init.Resolution = ADC_RESOLUTION_16B;
  hadc1.Init.ScanConvMode = ADC_SCAN_ENABLE;
  hadc1.Init.EOCSelection = ADC_EOC_SINGLE_CONV;
  hadc1.Init.LowPowerAutoWait = DISABLE;
  hadc1.Init.ContinuousConvMode = ENABLE;
  hadc1.Init.NbrOfConversion = 2;
  hadc1.Init.DiscontinuousConvMode = DISABLE;
  hadc1.Init.ExternalTrigConv = ADC_SOFTWARE_START;
  hadc1.Init.ExternalTrigConvEdge = ADC_EXTERNALTRIGCONVEDGE_NONE;
  hadc1.Init.ConversionDataManagement = ADC_CONVERSIONDATA_DMA_CIRCULAR;
  hadc1.Init.Overrun = ADC_OVR_DATA_PRESERVED;
  hadc1.Init.LeftBitShift = ADC_LEFTBITSHIFT_NONE;
  hadc1.Init.OversamplingMode = DISABLE;
  hadc1.Init.Oversampling.Ratio = 1;
  if (HAL_ADC_Init(&hadc1) != HAL_OK)
  {
    Error_Handler();
  }

  /** Configure the ADC multi-mode
  */
  multimode.Mode = ADC_MODE_INDEPENDENT;
  if (HAL_ADCEx_MultiModeConfigChannel(&hadc1, &multimode) != HAL_OK)
  {
    Error_Handler();
  }

  /** Configure Regular Channel
  */
  sConfig.Channel = ADC_CHANNEL_4;
  sConfig.Rank = ADC_REGULAR_RANK_1;
  sConfig.SamplingTime = ADC_SAMPLETIME_32CYCLES_5;
  sConfig.SingleDiff = ADC_SINGLE_ENDED;
  sConfig.OffsetNumber = ADC_OFFSET_NONE;
  sConfig.Offset = 0;
  sConfig.OffsetSignedSaturation = DISABLE;
  if (HAL_ADC_ConfigChannel(&hadc1, &sConfig) != HAL_OK)
  {
    Error_Handler();
  }

  /** Configure Regular Channel
  */
  sConfig.Channel = ADC_CHANNEL_19;
  sConfig.Rank = ADC_REGULAR_RANK_2;
  if (HAL_ADC_ConfigChannel(&hadc1, &sConfig) != HAL_OK)
  {
    Error_Handler();
  }

}

static void MX_FDCAN1_Init(void)
{

  hfdcan1.Instance = FDCAN1;
  hfdcan1.Init.FrameFormat = FDCAN_FRAME_CLASSIC;
  hfdcan1.Init.Mode = FDCAN_MODE_NORMAL;
  hfdcan1.Init.AutoRetransmission = ENABLE;
  hfdcan1.Init.TransmitPause = DISABLE;
  hfdcan1.Init.ProtocolException = DISABLE;
  hfdcan1.Init.NominalPrescaler = 3;
  hfdcan1.Init.NominalSyncJumpWidth = 1;
  hfdcan1.Init.NominalTimeSeg1 = 29;
  hfdcan1.Init.NominalTimeSeg2 = 10;
  hfdcan1.Init.DataPrescaler = 1;
  hfdcan1.Init.DataSyncJumpWidth = 1;
  hfdcan1.Init.DataTimeSeg1 = 1;
  hfdcan1.Init.DataTimeSeg2 = 1;
  hfdcan1.Init.MessageRAMOffset = 0;
  hfdcan1.Init.StdFiltersNbr = 1;
  hfdcan1.Init.ExtFiltersNbr = 0;
  hfdcan1.Init.RxFifo0ElmtsNbr = 32;
  hfdcan1.Init.RxFifo0ElmtSize = FDCAN_DATA_BYTES_8;
  hfdcan1.Init.RxFifo1ElmtsNbr = 0;
  hfdcan1.Init.RxFifo1ElmtSize = FDCAN_DATA_BYTES_8;
  hfdcan1.Init.RxBuffersNbr = 0;
  hfdcan1.Init.RxBufferSize = FDCAN_DATA_BYTES_8;
  hfdcan1.Init.TxEventsNbr = 0;
  hfdcan1.Init.TxBuffersNbr = 0;
  hfdcan1.Init.TxFifoQueueElmtsNbr = 32;
  hfdcan1.Init.TxFifoQueueMode = FDCAN_TX_FIFO_OPERATION;
  hfdcan1.Init.TxElmtSize = FDCAN_DATA_BYTES_8;
  if (HAL_FDCAN_Init(&hfdcan1) != HAL_OK)
  {
    Error_Handler();
  }

}

static void MX_FDCAN2_Init(void)
{

  hfdcan2.Instance = FDCAN2;
  hfdcan2.Init.FrameFormat = FDCAN_FRAME_CLASSIC;
  hfdcan2.Init.Mode = FDCAN_MODE_NORMAL;
  hfdcan2.Init.AutoRetransmission = ENABLE;
  hfdcan2.Init.TransmitPause = DISABLE;
  hfdcan2.Init.ProtocolException = DISABLE;
  hfdcan2.Init.NominalPrescaler = 3;
  hfdcan2.Init.NominalSyncJumpWidth = 1;
  hfdcan2.Init.NominalTimeSeg1 = 29;
  hfdcan2.Init.NominalTimeSeg2 = 10;
  hfdcan2.Init.DataPrescaler = 1;
  hfdcan2.Init.DataSyncJumpWidth = 1;
  hfdcan2.Init.DataTimeSeg1 = 1;
  hfdcan2.Init.DataTimeSeg2 = 1;
  hfdcan2.Init.MessageRAMOffset = 0x406;
  hfdcan2.Init.StdFiltersNbr = 1;
  hfdcan2.Init.ExtFiltersNbr = 0;
  hfdcan2.Init.RxFifo0ElmtsNbr = 0;
  hfdcan2.Init.RxFifo0ElmtSize = FDCAN_DATA_BYTES_8;
  hfdcan2.Init.RxFifo1ElmtsNbr = 32;
  hfdcan2.Init.RxFifo1ElmtSize = FDCAN_DATA_BYTES_8;
  hfdcan2.Init.RxBuffersNbr = 0;
  hfdcan2.Init.RxBufferSize = FDCAN_DATA_BYTES_8;
  hfdcan2.Init.TxEventsNbr = 8;
  hfdcan2.Init.TxBuffersNbr = 0;
  hfdcan2.Init.TxFifoQueueElmtsNbr = 32;
  hfdcan2.Init.TxFifoQueueMode = FDCAN_TX_FIFO_OPERATION;
  hfdcan2.Init.TxElmtSize = FDCAN_DATA_BYTES_8;
  if (HAL_FDCAN_Init(&hfdcan2) != HAL_OK)
  {
    Error_Handler();
  }

}

static void MX_FDCAN3_Init(void)
{

  hfdcan3.Instance = FDCAN3;
  hfdcan3.Init.FrameFormat = FDCAN_FRAME_CLASSIC;
  hfdcan3.Init.Mode = FDCAN_MODE_NORMAL;
  hfdcan3.Init.AutoRetransmission = ENABLE;
  hfdcan3.Init.TransmitPause = DISABLE;
  hfdcan3.Init.ProtocolException = DISABLE;
  hfdcan3.Init.NominalPrescaler = 3;
  hfdcan3.Init.NominalSyncJumpWidth = 1;
  hfdcan3.Init.NominalTimeSeg1 = 29;
  hfdcan3.Init.NominalTimeSeg2 = 10;
  hfdcan3.Init.DataPrescaler = 1;
  hfdcan3.Init.DataSyncJumpWidth = 1;
  hfdcan3.Init.DataTimeSeg1 = 1;
  hfdcan3.Init.DataTimeSeg2 = 1;
  hfdcan3.Init.MessageRAMOffset = 0x812;
  hfdcan3.Init.StdFiltersNbr = 1;
  hfdcan3.Init.ExtFiltersNbr = 0;
  hfdcan3.Init.RxFifo0ElmtsNbr = 0;
  hfdcan3.Init.RxFifo0ElmtSize = FDCAN_DATA_BYTES_8;
  hfdcan3.Init.RxFifo1ElmtsNbr = 32;
  hfdcan3.Init.RxFifo1ElmtSize = FDCAN_DATA_BYTES_8;
  hfdcan3.Init.RxBuffersNbr = 0;
  hfdcan3.Init.RxBufferSize = FDCAN_DATA_BYTES_8;
  hfdcan3.Init.TxEventsNbr = 4;
  hfdcan3.Init.TxBuffersNbr = 0;
  hfdcan3.Init.TxFifoQueueElmtsNbr = 32;
  hfdcan3.Init.TxFifoQueueMode = FDCAN_TX_FIFO_OPERATION;
  hfdcan3.Init.TxElmtSize = FDCAN_DATA_BYTES_8;
  if (HAL_FDCAN_Init(&hfdcan3) != HAL_OK)
  {
    Error_Handler();
  }

}

static void MX_SPI2_Init(void)
{

  /* SPI2 parameter configuration*/
  hspi2.Instance = SPI2;
  hspi2.Init.Mode = SPI_MODE_MASTER;
  hspi2.Init.Direction = SPI_DIRECTION_2LINES;
  hspi2.Init.DataSize = SPI_DATASIZE_8BIT;
  hspi2.Init.CLKPolarity = SPI_POLARITY_HIGH;
  hspi2.Init.CLKPhase = SPI_PHASE_2EDGE;
  hspi2.Init.NSS = SPI_NSS_SOFT;
  hspi2.Init.BaudRatePrescaler = SPI_BAUDRATEPRESCALER_32;
  hspi2.Init.FirstBit = SPI_FIRSTBIT_MSB;
  hspi2.Init.TIMode = SPI_TIMODE_DISABLE;
  hspi2.Init.CRCCalculation = SPI_CRCCALCULATION_DISABLE;
  hspi2.Init.CRCPolynomial = 0x0;
  hspi2.Init.NSSPMode = SPI_NSS_PULSE_ENABLE;
  hspi2.Init.NSSPolarity = SPI_NSS_POLARITY_LOW;
  hspi2.Init.FifoThreshold = SPI_FIFO_THRESHOLD_01DATA;
  hspi2.Init.TxCRCInitializationPattern = SPI_CRC_INITIALIZATION_ALL_ZERO_PATTERN;
  hspi2.Init.RxCRCInitializationPattern = SPI_CRC_INITIALIZATION_ALL_ZERO_PATTERN;
  hspi2.Init.MasterSSIdleness = SPI_MASTER_SS_IDLENESS_00CYCLE;
  hspi2.Init.MasterInterDataIdleness = SPI_MASTER_INTERDATA_IDLENESS_00CYCLE;
  hspi2.Init.MasterReceiverAutoSusp = SPI_MASTER_RX_AUTOSUSP_DISABLE;
  hspi2.Init.MasterKeepIOState = SPI_MASTER_KEEP_IO_STATE_DISABLE;
  hspi2.Init.IOSwap = SPI_IO_SWAP_DISABLE;
  if (HAL_SPI_Init(&hspi2) != HAL_OK)
  {
    Error_Handler();
  }

}

static void MX_SPI6_Init(void)
{

  /* SPI6 parameter configuration*/
  hspi6.Instance = SPI6;
  hspi6.Init.Mode = SPI_MODE_MASTER;
  hspi6.Init.Direction = SPI_DIRECTION_2LINES_TXONLY;
  hspi6.Init.DataSize = SPI_DATASIZE_8BIT;
  hspi6.Init.CLKPolarity = SPI_POLARITY_LOW;
  hspi6.Init.CLKPhase = SPI_PHASE_1EDGE;
  hspi6.Init.NSS = SPI_NSS_SOFT;
  hspi6.Init.BaudRatePrescaler = SPI_BAUDRATEPRESCALER_4;
  hspi6.Init.FirstBit = SPI_FIRSTBIT_MSB;
  hspi6.Init.TIMode = SPI_TIMODE_DISABLE;
  hspi6.Init.CRCCalculation = SPI_CRCCALCULATION_DISABLE;
  hspi6.Init.CRCPolynomial = 0x0;
  hspi6.Init.NSSPMode = SPI_NSS_PULSE_ENABLE;
  hspi6.Init.NSSPolarity = SPI_NSS_POLARITY_LOW;
  hspi6.Init.FifoThreshold = SPI_FIFO_THRESHOLD_01DATA;
  hspi6.Init.TxCRCInitializationPattern = SPI_CRC_INITIALIZATION_ALL_ZERO_PATTERN;
  hspi6.Init.RxCRCInitializationPattern = SPI_CRC_INITIALIZATION_ALL_ZERO_PATTERN;
  hspi6.Init.MasterSSIdleness = SPI_MASTER_SS_IDLENESS_00CYCLE;
  hspi6.Init.MasterInterDataIdleness = SPI_MASTER_INTERDATA_IDLENESS_00CYCLE;
  hspi6.Init.MasterReceiverAutoSusp = SPI_MASTER_RX_AUTOSUSP_DISABLE;
  hspi6.Init.MasterKeepIOState = SPI_MASTER_KEEP_IO_STATE_DISABLE;
  hspi6.Init.IOSwap = SPI_IO_SWAP_DISABLE;
  if (HAL_SPI_Init(&hspi6) != HAL_OK)
  {
    Error_Handler();
  }

}

static void MX_TIM3_Init(void)
{

  TIM_MasterConfigTypeDef sMasterConfig = {0};
  TIM_OC_InitTypeDef sConfigOC = {0};

  htim3.Instance = TIM3;
  htim3.Init.Prescaler = 240-1;
  htim3.Init.CounterMode = TIM_COUNTERMODE_UP;
  htim3.Init.Period = 10000-1;
  htim3.Init.ClockDivision = TIM_CLOCKDIVISION_DIV1;
  htim3.Init.AutoReloadPreload = TIM_AUTORELOAD_PRELOAD_DISABLE;
  if (HAL_TIM_PWM_Init(&htim3) != HAL_OK)
  {
    Error_Handler();
  }
  sMasterConfig.MasterOutputTrigger = TIM_TRGO_RESET;
  sMasterConfig.MasterSlaveMode = TIM_MASTERSLAVEMODE_DISABLE;
  if (HAL_TIMEx_MasterConfigSynchronization(&htim3, &sMasterConfig) != HAL_OK)
  {
    Error_Handler();
  }
  sConfigOC.OCMode = TIM_OCMODE_PWM1;
  sConfigOC.Pulse = 0;
  sConfigOC.OCPolarity = TIM_OCPOLARITY_HIGH;
  sConfigOC.OCFastMode = TIM_OCFAST_DISABLE;
  if (HAL_TIM_PWM_ConfigChannel(&htim3, &sConfigOC, TIM_CHANNEL_4) != HAL_OK)
  {
    Error_Handler();
  }
  HAL_TIM_MspPostInit(&htim3);

}

static void MX_TIM12_Init(void)
{

  TIM_MasterConfigTypeDef sMasterConfig = {0};
  TIM_OC_InitTypeDef sConfigOC = {0};

  htim12.Instance = TIM12;
  htim12.Init.Prescaler = 240-1;
  htim12.Init.CounterMode = TIM_COUNTERMODE_UP;
  htim12.Init.Period = 250-1;
  htim12.Init.ClockDivision = TIM_CLOCKDIVISION_DIV1;
  htim12.Init.AutoReloadPreload = TIM_AUTORELOAD_PRELOAD_DISABLE;
  if (HAL_TIM_PWM_Init(&htim12) != HAL_OK)
  {
    Error_Handler();
  }
  sMasterConfig.MasterOutputTrigger = TIM_TRGO_RESET;
  sMasterConfig.MasterSlaveMode = TIM_MASTERSLAVEMODE_DISABLE;
  if (HAL_TIMEx_MasterConfigSynchronization(&htim12, &sMasterConfig) != HAL_OK)
  {
    Error_Handler();
  }
  sConfigOC.OCMode = TIM_OCMODE_PWM1;
  sConfigOC.Pulse = 0;
  sConfigOC.OCPolarity = TIM_OCPOLARITY_HIGH;
  sConfigOC.OCFastMode = TIM_OCFAST_DISABLE;
  if (HAL_TIM_PWM_ConfigChannel(&htim12, &sConfigOC, TIM_CHANNEL_2) != HAL_OK)
  {
    Error_Handler();
  }
  __HAL_TIM_DISABLE_OCxPRELOAD(&htim12, TIM_CHANNEL_2);
  HAL_TIM_MspPostInit(&htim12);

}

static void MX_UART5_Init(void)
{

  huart5.Instance = UART5;
  huart5.Init.BaudRate = 100000;
  huart5.Init.WordLength = UART_WORDLENGTH_9B;
  huart5.Init.StopBits = UART_STOPBITS_2;
  huart5.Init.Parity = UART_PARITY_EVEN;
  huart5.Init.Mode = UART_MODE_RX;
  huart5.Init.HwFlowCtl = UART_HWCONTROL_NONE;
  huart5.Init.OverSampling = UART_OVERSAMPLING_16;
  huart5.Init.OneBitSampling = UART_ONE_BIT_SAMPLE_DISABLE;
  huart5.Init.ClockPrescaler = UART_PRESCALER_DIV1;
  huart5.AdvancedInit.AdvFeatureInit = UART_ADVFEATURE_NO_INIT;
  if (HAL_UART_Init(&huart5) != HAL_OK)
  {
    Error_Handler();
  }
  if (HAL_UARTEx_SetTxFifoThreshold(&huart5, UART_TXFIFO_THRESHOLD_1_8) != HAL_OK)
  {
    Error_Handler();
  }
  if (HAL_UARTEx_SetRxFifoThreshold(&huart5, UART_RXFIFO_THRESHOLD_1_8) != HAL_OK)
  {
    Error_Handler();
  }
  if (HAL_UARTEx_DisableFifoMode(&huart5) != HAL_OK)
  {
    Error_Handler();
  }

}

static void MX_UART7_Init(void)
{

  huart7.Instance = UART7;
  huart7.Init.BaudRate = 921600;
  huart7.Init.WordLength = UART_WORDLENGTH_8B;
  huart7.Init.StopBits = UART_STOPBITS_1;
  huart7.Init.Parity = UART_PARITY_NONE;
  huart7.Init.Mode = UART_MODE_TX_RX;
  huart7.Init.HwFlowCtl = UART_HWCONTROL_NONE;
  huart7.Init.OverSampling = UART_OVERSAMPLING_16;
  huart7.Init.OneBitSampling = UART_ONE_BIT_SAMPLE_DISABLE;
  huart7.Init.ClockPrescaler = UART_PRESCALER_DIV1;
  huart7.AdvancedInit.AdvFeatureInit = UART_ADVFEATURE_NO_INIT;
  if (HAL_UART_Init(&huart7) != HAL_OK)
  {
    Error_Handler();
  }
  if (HAL_UARTEx_SetTxFifoThreshold(&huart7, UART_TXFIFO_THRESHOLD_1_8) != HAL_OK)
  {
    Error_Handler();
  }
  if (HAL_UARTEx_SetRxFifoThreshold(&huart7, UART_RXFIFO_THRESHOLD_1_8) != HAL_OK)
  {
    Error_Handler();
  }
  if (HAL_UARTEx_DisableFifoMode(&huart7) != HAL_OK)
  {
    Error_Handler();
  }

}

static void MX_USART1_UART_Init(void)
{

  huart1.Instance = USART1;
  huart1.Init.BaudRate = 921600;
  huart1.Init.WordLength = UART_WORDLENGTH_8B;
  huart1.Init.StopBits = UART_STOPBITS_1;
  huart1.Init.Parity = UART_PARITY_NONE;
  huart1.Init.Mode = UART_MODE_TX_RX;
  huart1.Init.HwFlowCtl = UART_HWCONTROL_NONE;
  huart1.Init.OverSampling = UART_OVERSAMPLING_16;
  huart1.Init.OneBitSampling = UART_ONE_BIT_SAMPLE_DISABLE;
  huart1.Init.ClockPrescaler = UART_PRESCALER_DIV1;
  huart1.AdvancedInit.AdvFeatureInit = UART_ADVFEATURE_NO_INIT;
  if (HAL_UART_Init(&huart1) != HAL_OK)
  {
    Error_Handler();
  }
  if (HAL_UARTEx_SetTxFifoThreshold(&huart1, UART_TXFIFO_THRESHOLD_1_8) != HAL_OK)
  {
    Error_Handler();
  }
  if (HAL_UARTEx_SetRxFifoThreshold(&huart1, UART_RXFIFO_THRESHOLD_1_8) != HAL_OK)
  {
    Error_Handler();
  }
  if (HAL_UARTEx_DisableFifoMode(&huart1) != HAL_OK)
  {
    Error_Handler();
  }

}

static void MX_USART2_UART_Init(void)
{

  huart2.Instance = USART2;
  huart2.Init.BaudRate = 921600;
  huart2.Init.WordLength = UART_WORDLENGTH_8B;
  huart2.Init.StopBits = UART_STOPBITS_1;
  huart2.Init.Parity = UART_PARITY_NONE;
  huart2.Init.Mode = UART_MODE_TX_RX;
  huart2.Init.HwFlowCtl = UART_HWCONTROL_NONE;
  huart2.Init.OverSampling = UART_OVERSAMPLING_16;
  huart2.Init.OneBitSampling = UART_ONE_BIT_SAMPLE_DISABLE;
  huart2.Init.ClockPrescaler = UART_PRESCALER_DIV1;
  huart2.AdvancedInit.AdvFeatureInit = UART_ADVFEATURE_NO_INIT;
  if (HAL_UART_Init(&huart2) != HAL_OK)
  {
    Error_Handler();
  }
  if (HAL_UARTEx_SetTxFifoThreshold(&huart2, UART_TXFIFO_THRESHOLD_1_8) != HAL_OK)
  {
    Error_Handler();
  }
  if (HAL_UARTEx_SetRxFifoThreshold(&huart2, UART_RXFIFO_THRESHOLD_1_8) != HAL_OK)
  {
    Error_Handler();
  }
  if (HAL_UARTEx_DisableFifoMode(&huart2) != HAL_OK)
  {
    Error_Handler();
  }

}

static void MX_USART3_UART_Init(void)
{

  huart3.Instance = USART3;
  huart3.Init.BaudRate = 921600;
  huart3.Init.WordLength = UART_WORDLENGTH_8B;
  huart3.Init.StopBits = UART_STOPBITS_1;
  huart3.Init.Parity = UART_PARITY_NONE;
  huart3.Init.Mode = UART_MODE_TX_RX;
  huart3.Init.HwFlowCtl = UART_HWCONTROL_NONE;
  huart3.Init.OverSampling = UART_OVERSAMPLING_16;
  huart3.Init.OneBitSampling = UART_ONE_BIT_SAMPLE_DISABLE;
  huart3.Init.ClockPrescaler = UART_PRESCALER_DIV1;
  huart3.AdvancedInit.AdvFeatureInit = UART_ADVFEATURE_NO_INIT;
  if (HAL_UART_Init(&huart3) != HAL_OK)
  {
    Error_Handler();
  }
  if (HAL_UARTEx_SetTxFifoThreshold(&huart3, UART_TXFIFO_THRESHOLD_1_8) != HAL_OK)
  {
    Error_Handler();
  }
  if (HAL_UARTEx_SetRxFifoThreshold(&huart3, UART_RXFIFO_THRESHOLD_1_8) != HAL_OK)
  {
    Error_Handler();
  }
  if (HAL_UARTEx_DisableFifoMode(&huart3) != HAL_OK)
  {
    Error_Handler();
  }

}

static void MX_USART10_UART_Init(void)
{

  huart10.Instance = USART10;
  huart10.Init.BaudRate = 921600;
  huart10.Init.WordLength = UART_WORDLENGTH_8B;
  huart10.Init.StopBits = UART_STOPBITS_1;
  huart10.Init.Parity = UART_PARITY_NONE;
  huart10.Init.Mode = UART_MODE_TX_RX;
  huart10.Init.HwFlowCtl = UART_HWCONTROL_NONE;
  huart10.Init.OverSampling = UART_OVERSAMPLING_16;
  huart10.Init.OneBitSampling = UART_ONE_BIT_SAMPLE_DISABLE;
  huart10.Init.ClockPrescaler = UART_PRESCALER_DIV1;
  huart10.AdvancedInit.AdvFeatureInit = UART_ADVFEATURE_NO_INIT;
  if (HAL_UART_Init(&huart10) != HAL_OK)
  {
    Error_Handler();
  }
  if (HAL_UARTEx_SetTxFifoThreshold(&huart10, UART_TXFIFO_THRESHOLD_1_8) != HAL_OK)
  {
    Error_Handler();
  }
  if (HAL_UARTEx_SetRxFifoThreshold(&huart10, UART_RXFIFO_THRESHOLD_1_8) != HAL_OK)
  {
    Error_Handler();
  }
  if (HAL_UARTEx_DisableFifoMode(&huart10) != HAL_OK)
  {
    Error_Handler();
  }

}

static void MX_DMA_Init(void)
{

  /* DMA controller clock enable */
  __HAL_RCC_DMA1_CLK_ENABLE();
  __HAL_RCC_DMA2_CLK_ENABLE();

  /* DMA interrupt init */
  /* DMA1_Stream0_IRQn interrupt configuration */
  HAL_NVIC_SetPriority(DMA1_Stream0_IRQn, 5, 0);
  HAL_NVIC_EnableIRQ(DMA1_Stream0_IRQn);
  /* DMA1_Stream1_IRQn interrupt configuration */
  HAL_NVIC_SetPriority(DMA1_Stream1_IRQn, 5, 0);
  HAL_NVIC_EnableIRQ(DMA1_Stream1_IRQn);
  /* DMA1_Stream2_IRQn interrupt configuration */
  HAL_NVIC_SetPriority(DMA1_Stream2_IRQn, 5, 0);
  HAL_NVIC_EnableIRQ(DMA1_Stream2_IRQn);
  /* DMA1_Stream3_IRQn interrupt configuration */
  HAL_NVIC_SetPriority(DMA1_Stream3_IRQn, 5, 0);
  HAL_NVIC_EnableIRQ(DMA1_Stream3_IRQn);
  /* DMA1_Stream4_IRQn interrupt configuration */
  HAL_NVIC_SetPriority(DMA1_Stream4_IRQn, 5, 0);
  HAL_NVIC_EnableIRQ(DMA1_Stream4_IRQn);
  /* DMA1_Stream5_IRQn interrupt configuration */
  HAL_NVIC_SetPriority(DMA1_Stream5_IRQn, 5, 0);
  HAL_NVIC_EnableIRQ(DMA1_Stream5_IRQn);
  /* DMA1_Stream6_IRQn interrupt configuration */
  HAL_NVIC_SetPriority(DMA1_Stream6_IRQn, 5, 0);
  HAL_NVIC_EnableIRQ(DMA1_Stream6_IRQn);
  /* DMA1_Stream7_IRQn interrupt configuration */
  HAL_NVIC_SetPriority(DMA1_Stream7_IRQn, 5, 0);
  HAL_NVIC_EnableIRQ(DMA1_Stream7_IRQn);
  /* DMA2_Stream0_IRQn interrupt configuration */
  HAL_NVIC_SetPriority(DMA2_Stream0_IRQn, 5, 0);
  HAL_NVIC_EnableIRQ(DMA2_Stream0_IRQn);
  /* DMA2_Stream1_IRQn interrupt configuration */
  HAL_NVIC_SetPriority(DMA2_Stream1_IRQn, 5, 0);
  HAL_NVIC_EnableIRQ(DMA2_Stream1_IRQn);
  /* DMA2_Stream2_IRQn interrupt configuration */
  HAL_NVIC_SetPriority(DMA2_Stream2_IRQn, 5, 0);
  HAL_NVIC_EnableIRQ(DMA2_Stream2_IRQn);
  /* DMA2_Stream3_IRQn interrupt configuration */
  HAL_NVIC_SetPriority(DMA2_Stream3_IRQn, 5, 0);
  HAL_NVIC_EnableIRQ(DMA2_Stream3_IRQn);
  /* DMA2_Stream4_IRQn interrupt configuration */
  HAL_NVIC_SetPriority(DMA2_Stream4_IRQn, 5, 0);
  HAL_NVIC_EnableIRQ(DMA2_Stream4_IRQn);
  /* DMA2_Stream5_IRQn interrupt configuration */
  HAL_NVIC_SetPriority(DMA2_Stream5_IRQn, 5, 0);
  HAL_NVIC_EnableIRQ(DMA2_Stream5_IRQn);

}

static void MX_GPIO_Init(void)
{
  GPIO_InitTypeDef GPIO_InitStruct = {0};

  /* GPIO Ports Clock Enable */
  __HAL_RCC_GPIOE_CLK_ENABLE();
  __HAL_RCC_GPIOH_CLK_ENABLE();
  __HAL_RCC_GPIOC_CLK_ENABLE();
  __HAL_RCC_GPIOA_CLK_ENABLE();
  __HAL_RCC_GPIOB_CLK_ENABLE();
  __HAL_RCC_GPIOD_CLK_ENABLE();

  /*Configure GPIO pin Output Level */
  HAL_GPIO_WritePin(GPIOC, ACC_CS_Pin|GYRO_CS_Pin, GPIO_PIN_SET);

  /*Configure GPIO pins : ACC_CS_Pin GYRO_CS_Pin */
  GPIO_InitStruct.Pin = ACC_CS_Pin|GYRO_CS_Pin;
  GPIO_InitStruct.Mode = GPIO_MODE_OUTPUT_PP;
  GPIO_InitStruct.Pull = GPIO_NOPULL;
  GPIO_InitStruct.Speed = GPIO_SPEED_FREQ_VERY_HIGH;
  HAL_GPIO_Init(GPIOC, &GPIO_InitStruct);

  /*Configure GPIO pins : ACC_INT_Pin GYRO_INT_Pin */
  GPIO_InitStruct.Pin = ACC_INT_Pin|GYRO_INT_Pin;
  GPIO_InitStruct.Mode = GPIO_MODE_IT_RISING;
  GPIO_InitStruct.Pull = GPIO_NOPULL;
  HAL_GPIO_Init(GPIOE, &GPIO_InitStruct);

  /*AnalogSwitch Config */
  HAL_SYSCFG_AnalogSwitchConfig(SYSCFG_SWITCH_PC3, SYSCFG_SWITCH_PC3_CLOSE);

  /* EXTI interrupt init*/
  HAL_NVIC_SetPriority(ACC_INT_EXTI_IRQn, 5, 0);
  HAL_NVIC_EnableIRQ(ACC_INT_EXTI_IRQn);

  /* USER CODE BEGIN MX_GPIO_Init_2 */
  HAL_GPIO_WritePin(GPIOC, ACC_CS_Pin|GYRO_CS_Pin, GPIO_PIN_SET);

  GPIO_InitStruct.Pin = ACC_CS_Pin|GYRO_CS_Pin;
  GPIO_InitStruct.Mode = GPIO_MODE_OUTPUT_PP;
  GPIO_InitStruct.Pull = GPIO_NOPULL;
  GPIO_InitStruct.Speed = GPIO_SPEED_FREQ_VERY_HIGH;
  HAL_GPIO_Init(GPIOC, &GPIO_InitStruct);
  HAL_SYSCFG_AnalogSwitchConfig(SYSCFG_SWITCH_PC3, SYSCFG_SWITCH_PC3_CLOSE);

  GPIO_InitStruct.Pin = ACC_INT_Pin|GYRO_INT_Pin;
  GPIO_InitStruct.Mode = GPIO_MODE_IT_RISING;
  GPIO_InitStruct.Pull = GPIO_NOPULL;
  HAL_GPIO_Init(GPIOE, &GPIO_InitStruct);
  HAL_NVIC_SetPriority(EXTI15_10_IRQn, 5, 0);
  HAL_NVIC_EnableIRQ(EXTI15_10_IRQn);

  /* USER CODE END MX_GPIO_Init_2 */
}

/* USER CODE BEGIN 4 */
void Board_Heater_SetDutyPermyriad(uint16_t duty)
{
  if (duty > 10000U)
  {
    duty = 10000U;
  }
  __HAL_TIM_SET_COMPARE(&htim3, TIM_CHANNEL_4, duty);
}

HAL_StatusTypeDef Board_Buzzer_SetTone(uint32_t frequency_hz, uint8_t volume_percent)
{
  if (frequency_hz == 0U || volume_percent == 0U)
  {
    __HAL_TIM_SET_COMPARE(&htim12, TIM_CHANNEL_2, 0);
    return HAL_OK;
  }
  if (frequency_hz < 20U || frequency_hz > 20000U || volume_percent > 100U)
  {
    return HAL_ERROR;
  }

  uint32_t period = (1000000U + frequency_hz / 2U) / frequency_hz;
  __HAL_TIM_SET_COMPARE(&htim12, TIM_CHANNEL_2, 0);
  __HAL_TIM_SET_AUTORELOAD(&htim12, period - 1U);
  __HAL_TIM_SET_COUNTER(&htim12, 0);
  __HAL_TIM_SET_COMPARE(&htim12, TIM_CHANNEL_2, period * volume_percent / 200U);
  return HAL_OK;
}

/* USER CODE END 4 */

void StartDefaultTask(void *argument)
{
  /* init code for USB_DEVICE */
  MX_USB_DEVICE_Init();
  for(;;)
  {
    osDelay(1);
  }
}

 /* MPU Configuration */

void MPU_Config(void)
{
  MPU_Region_InitTypeDef MPU_InitStruct = {0};

  /* Disables the MPU */
  HAL_MPU_Disable();

  /** Initializes and configures the Region and the memory to be protected
  */
  MPU_InitStruct.Enable = MPU_REGION_ENABLE;
  MPU_InitStruct.Number = MPU_REGION_NUMBER0;
  MPU_InitStruct.BaseAddress = 0x0;
  MPU_InitStruct.Size = MPU_REGION_SIZE_4GB;
  MPU_InitStruct.SubRegionDisable = 0x87;
  MPU_InitStruct.TypeExtField = MPU_TEX_LEVEL0;
  MPU_InitStruct.AccessPermission = MPU_REGION_NO_ACCESS;
  MPU_InitStruct.DisableExec = MPU_INSTRUCTION_ACCESS_DISABLE;
  MPU_InitStruct.IsShareable = MPU_ACCESS_SHAREABLE;
  MPU_InitStruct.IsCacheable = MPU_ACCESS_NOT_CACHEABLE;
  MPU_InitStruct.IsBufferable = MPU_ACCESS_NOT_BUFFERABLE;

  HAL_MPU_ConfigRegion(&MPU_InitStruct);
  /* Enables the MPU */
  HAL_MPU_Enable(MPU_PRIVILEGED_DEFAULT);

}

void HAL_TIM_PeriodElapsedCallback(TIM_HandleTypeDef *htim)
{
  if (htim->Instance == TIM4)
  {
    HAL_IncTick();
  }
}

void Error_Handler(void)
{
  __disable_irq();
  while (1)
  {
  }
}
